# EFM32PG22C200F512IM32 register map
Vendor: Silicon Labs; Series: EFM32; File version: C
Registers are 32-bit, read-write, reset 0x0 unless marked. A register's access mark holds for its fields unless they carry their own. Offsets are from the block's base; [hi:lo] are bit positions.

## WDOG0_S — WDOG0_S Registers
Base 0x4A018000
Same registers: WDOG0_NS 0x5A018000
0x00 IPVERSION ro
0x04 EN
  [0] EN — Module Enable
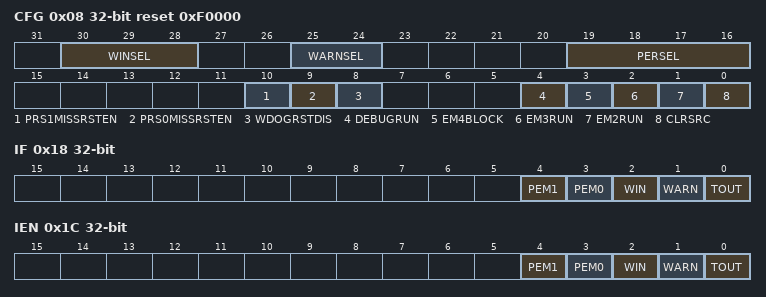
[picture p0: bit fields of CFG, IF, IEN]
0x08 CFG reset 0xF0000
  [30:28] WINSEL — WDOG Illegal Window Select
    0=DIS (Disabled.); 1=SEL1 (Window timeout is 12.5% of the Timeout.); 2=SEL2 (Window timeout is 25% of the Timeout.); 3=SEL3 (Window timeout is 37.5% of the Timeout.); 4=SEL4 (Window timeout is 50% of the Timeout.); 5=SEL5 (Window timeout is 62.5% of the Timeout.); 6=SEL6 (Window timeout is 75.5% of the Timeout.); 7=SEL7 (Window timeout is 87.5% of the Timeout.)
  [25:24] WARNSEL — WDOG Warning Period Select
    0=DIS (Disable); 1=SEL1 (Warning timeout is 25% of the Timeout.); 2=SEL2 (Warning timeout is 50% of the Timeout.); 3=SEL3 (Warning timeout is 75% of the Timeout.)
  [19:16] PERSEL — WDOG Timeout Period Select
    0=SEL0 (Timeout period of 9 wdog cycles); 1=SEL1 (Timeout period of 17 wdog cycles); 2=SEL2 (Timeout period of 33 wdog cycles); 3=SEL3 (Timeout period of 65 wdog cycles); 4=SEL4 (Timeout period of 129 wdog cycles); 5=SEL5 (Timeout period of 257 wdog cycles); 6=SEL6 (Timeout period of 513 wdog cycles); 7=SEL7 (Timeout period of 1k wdog cycles); 8=SEL8 (Timeout period of 2k wdog cycles); 9=SEL9 (Timeout period of 4k wdog cycles); 10=SEL10 (Timeout period of 8k wdog cycles); 11=SEL11 (Timeout period of 16k wdog cycles); 12=SEL12 (Timeout period of 32k wdog cycles); 13=SEL13 (Timeout period of 64k wdog cycles); 14=SEL14 (Timeout period of 128k wdog cycles); 15=SEL15 (Timeout period of 256k wdog cycles)
  [10] PRS1MISSRSTEN — PRS Src1 Missing Event WDOG Reset
  [9] PRS0MISSRSTEN — PRS Src0 Missing Event WDOG Reset
  [8] WDOGRSTDIS — WDOG Reset Disable
    0=EN (A timeout will cause a WDOG reset); 1=DIS (A timeout will not cause a WDOG reset)
  [4] DEBUGRUN — Debug Mode Run
    0=DISABLE (WDOG timer is frozen in debug mode); 1=ENABLE (WDOG timer is running in debug mode)
  [3] EM4BLOCK
    0=DISABLE (EM4 can be entered by software. See EMU for detailed description.); 1=ENABLE (EM4 cannot be entered by software.)
  [2] EM3RUN
    0=DISABLE (WDOG timer is frozen in EM3.); 1=ENABLE (WDOG timer is running in EM3.)
  [1] EM2RUN
    0=DISABLE (WDOG timer is frozen in EM2.); 1=ENABLE (WDOG timer is running in EM2.)
  [0] CLRSRC — WDOG Clear Source
    0=SW (A write to the clear bit will clear the WDOG counter); 1=PRSSRC0 (A rising edge on the PRS Source 0 will clear the WDOG counter)
0x0C CMD wo
  [0] CLEAR — WDOG Timer Clear
    0=UNCHANGED (WDOG timer is unchanged.); 1=CLEARED (WDOG timer is cleared to 0.)
0x14 STATUS ro
  [31] LOCK — WDOG Configuration Lock Status
    0=UNLOCKED (All WDOG lockable registers are unlocked.); 1=LOCKED (All WDOG lockable registers are locked.)
0x18 IF
  [4] PEM1 — PRS Src1 Event Missing Interrupt Flag
  [3] PEM0 — PRS Src0 Event Missing Interrupt Flag
  [2] WIN — WDOG Window Interrupt Flag
  [1] WARN — WDOG Warning Timeout Interrupt Flag
  [0] TOUT — WDOG Timeout Interrupt Flag
0x1C IEN
  [4] PEM1 — PRS Src1 Event Missing Interrupt Enable
  [3] PEM0 — PRS Src0 Event Missing Interrupt Enable
  [2] WIN — WDOG Window Interrupt Enable
  [1] WARN — WDOG Warning Timeout Interrupt Enable
  [0] TOUT — WDOG Timeout Interrupt Enable
0x20 LOCK wo reset 0xABE8
  [15:0] LOCKKEY — WDOG Configuration Lock
    0=LOCK (Lock WDOG lockable registers); 0xABE8=UNLOCK (Unlock WDOG lockable registers)
0x24 SYNCBUSY ro
  [0] CMD — Sync Busy for Cmd Register

## AMUXCP0_S — AMUXCP0_S Registers
Base 0x4A020000
Same registers: AMUXCP0_NS 0x5A020000
0x00 IPVERSION ro reset 0x1
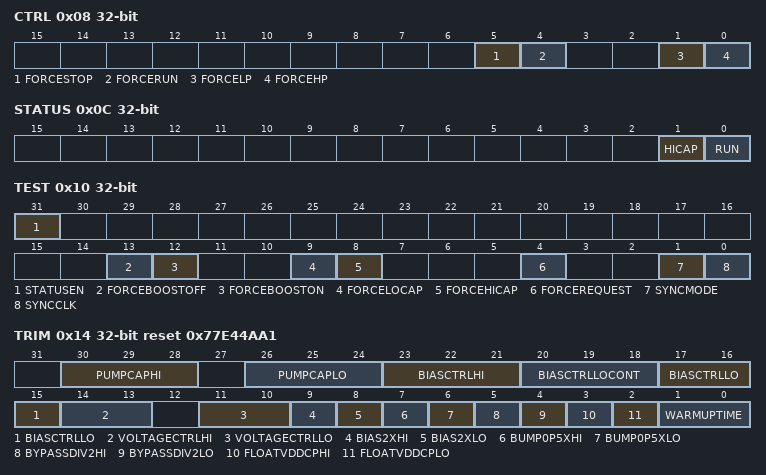
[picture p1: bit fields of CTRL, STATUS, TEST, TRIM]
0x08 CTRL — Control
  [5] FORCESTOP
  [4] FORCERUN
  [1] FORCELP — Force Low Power
  [0] FORCEHP — Force High Power
0x0C STATUS ro
  [1] HICAP — high cap
  [0] RUN — running
0x10 TEST
  [31] STATUSEN — Enable write to status bits
  [13] FORCEBOOSTOFF
  [12] FORCEBOOSTON
  [9] FORCELOCAP — Force low capacitance driver
  [8] FORCEHICAP — Force high capacitance driver
  [4] FORCEREQUEST
  [1] SYNCMODE
  [0] SYNCCLK — Sync Clock
0x14 TRIM reset 0x77E44AA1
  [30:28] PUMPCAPHI — Pump Cap High Power
  [26:24] PUMPCAPLO — Pump Cap Low Power
  [23:21] BIASCTRLHI — Bias Control High Power
  [20:18] BIASCTRLLOCONT — Bias Control Low Power Continuous
  [17:15] BIASCTRLLO — Bias Control Low Power
  [14:13] VOLTAGECTRLHI — Charge Pump Voltage Control High Power
  [11:10] VOLTAGECTRLLO — Charge Pump Voltage Control Low Power
  [9] BIAS2XHI — Bias 2x High Power
  [8] BIAS2XLO — Bias 2x Low Power
  [7] BUMP0P5XHI — Bump 0.5X High Power
  [6] BUMP0P5XLO — Bump 0.5X Low Power
  [5] BYPASSDIV2HI — Bypass Div2 High Power
  [4] BYPASSDIV2LO — Bypass Div2 Low Power
  [3] FLOATVDDCPHI — Float VDDCP High Power
  [2] FLOATVDDCPLO — Float VDDCP Low Power
  [1:0] WARMUPTIME
    0=WUCYCLES72 (Warm up cycle = 72; 3.6us @20 MHz); 1=WUCYCLES96 (Warm up cycle = 96; 4.8us @ 20 MHz); 2=WUCYCLES128 (Warm up cycle = 128; 6.4us @ 20 MHz); 3=WUCYCLES160 (Warm up cycle = 160; 8.0us @ 20 MHz)

## CRYPTOACC_S_PKCTRL — CRYPTOACC_S_PKCTRL Registers
Base 0x4C022000
Same registers: CRYPTOACC_NS_PKCTRL 0x5C022000
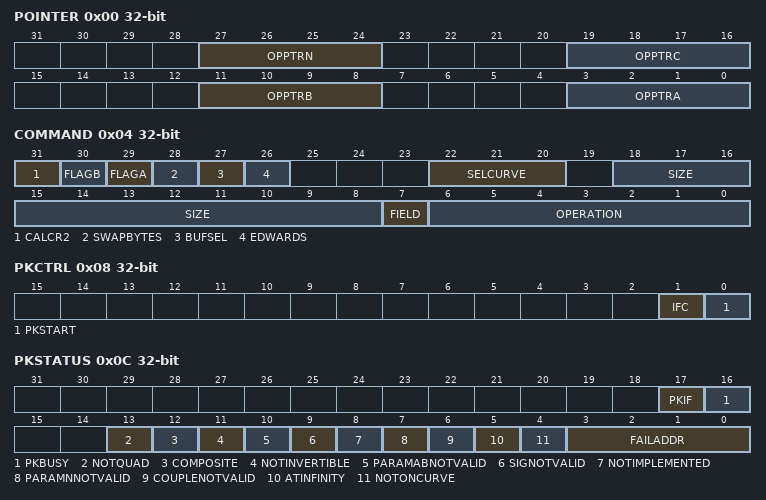
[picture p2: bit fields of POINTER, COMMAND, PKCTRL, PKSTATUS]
0x00 POINTER
  [27:24] OPPTRN, [19:16] OPPTRC, [11:8] OPPTRB, [3:0] OPPTRA
0x04 COMMAND
  [31] CALCR2 — Calculate R2
    0=FALSE (don't recalculate R² mod N); 1=TRUE (re-calculate R² mod N)
  [30] FLAGB
  [29] FLAGA
  [28] SWAPBYTES
    0=NATIVE (Native format (little endian)); 1=SWAPPED (Byte swapped (big endian))
  [27] BUFSEL — Buffer Select
    0=MEM0 (use data in data memory 0)
  [26] EDWARDS — Edwards Curve Enable
  [22:20] SELCURVE — Select Curve
    0=NONE (No acceleration); 1=P256; 4=P192
  [18:8] SIZE — Size of Operands in data memory
  [7] FIELD
    0=GFP (Field is GF(p)); 1=GF2M (Field is GF(2^m))
  [6:0] OPERATION — Type of Operation
0x08 PKCTRL wo
  [1] IFC — ClearIRQ
  [0] PKSTART
0x0C PKSTATUS ro
  [17] PKIF — Interrupt status
  [16] PKBUSY
  [13] NOTQUAD — Not quadratic residue
  [12] COMPOSITE
    0=FALSE (random number under test is probably prime); 1=TRUE (random number under test is composite)
  [11] NOTINVERTIBLE
  [10] PARAMABNOTVALID
  [9] SIGNOTVALID — Signature not valid
  [8] NOTIMPLEMENTED
  [7] PARAMNNOTVALID
  [6] COUPLENOTVALID
  [5] ATINFINITY — Point Px at infinity
  [4] NOTONCURVE — Point Px not on curve
  [3:0] FAILADDR — Fail Address
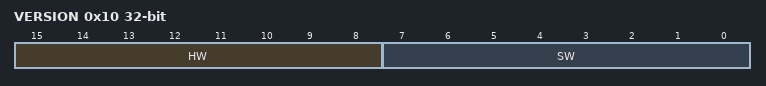
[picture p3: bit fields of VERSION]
0x10 VERSION ro
  [15:8] HW — Hardware version number
  [7:0] SW — Software version number
0x14 TIMER ro
